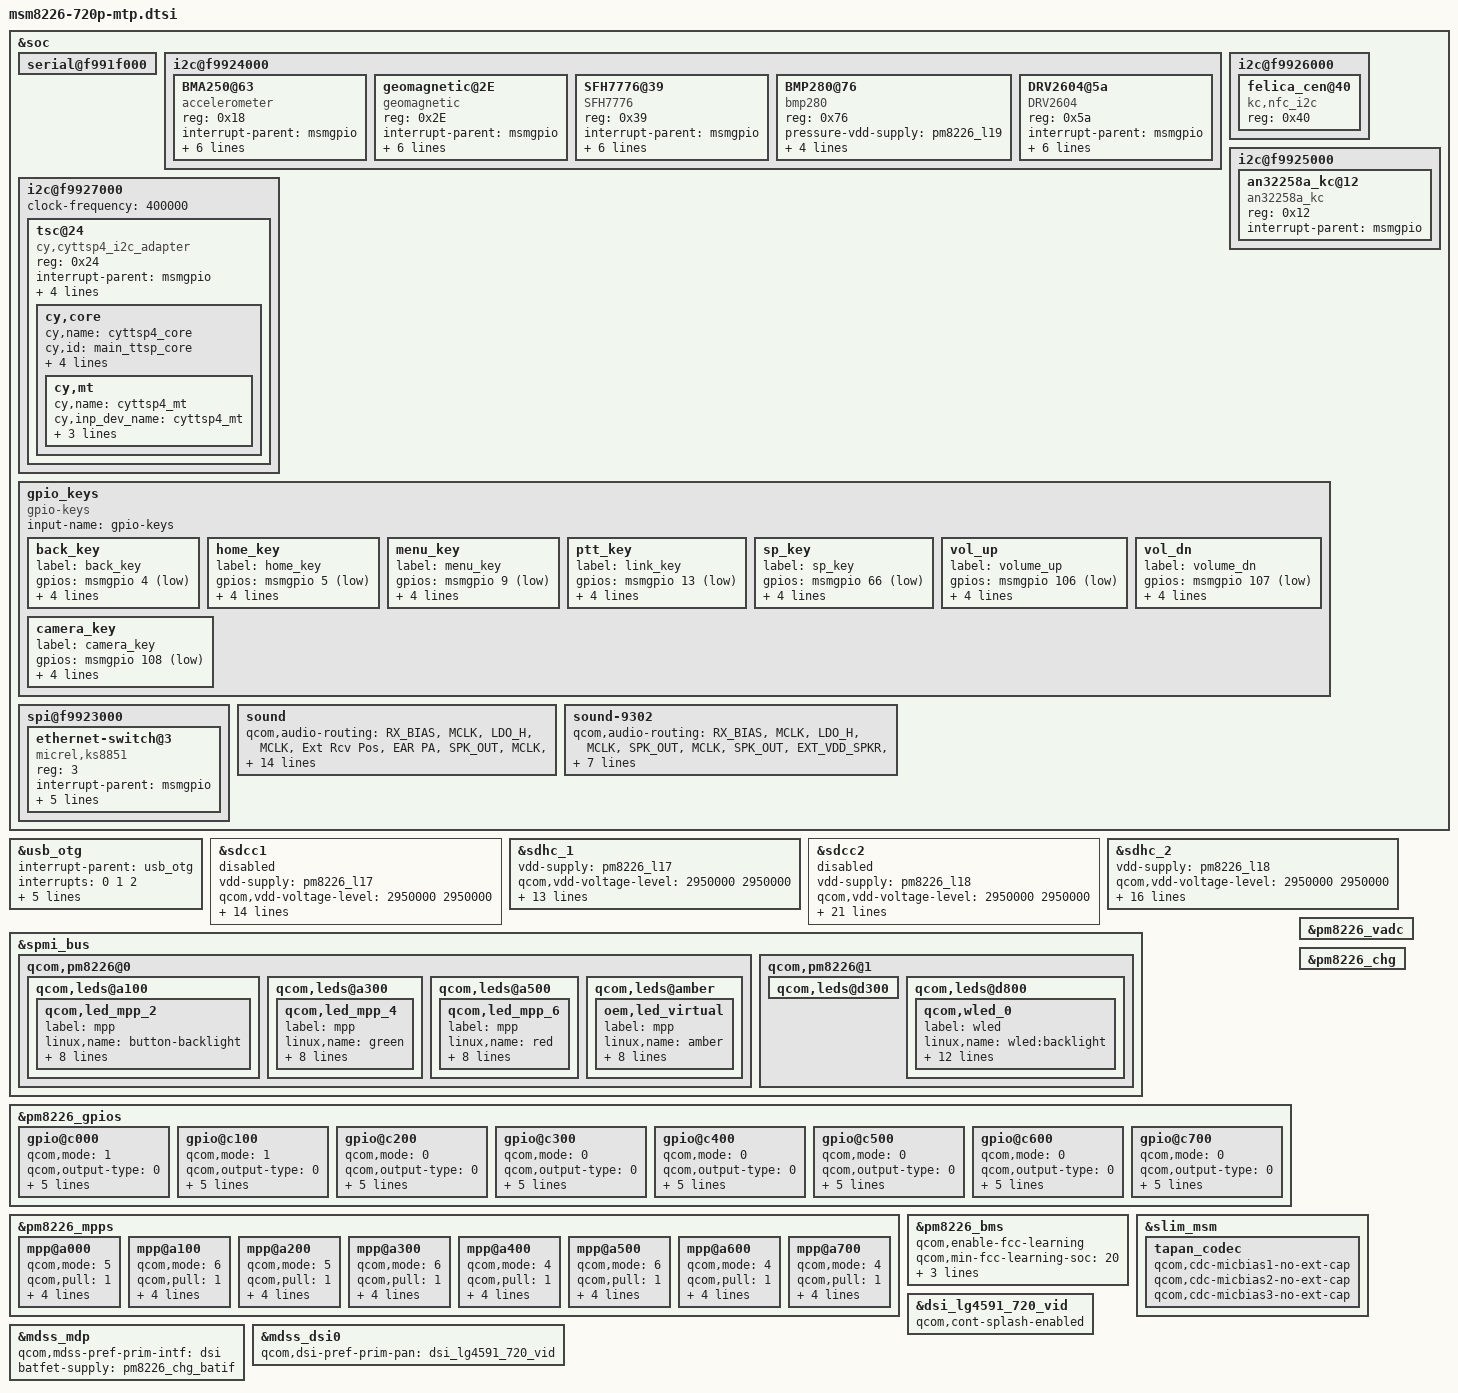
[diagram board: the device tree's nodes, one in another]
/* Copyright (c) 2013, The Linux Foundation. All rights reserved.
 *
 * This program is free software; you can redistribute it and/or modify
 * it under the terms of the GNU General Public License version 2 and
 * only version 2 as published by the Free Software Foundation.
 *
 * This program is distributed in the hope that it will be useful,
 * but WITHOUT ANY WARRANTY; without even the implied warranty of
 * MERCHANTABILITY or FITNESS FOR A PARTICULAR PURPOSE.  See the
 * GNU General Public License for more details.
 */
/*
 * This software is contributed or developed by KYOCERA Corporation.
 * (C) 2014 KYOCERA Corporation
 */

/include/ "msm8226-camera-sensor-mtp.dtsi"

&soc {
	serial@f991f000 {
		status = "ok";
	};
	i2c@f9924000 {
		BMA250@63 {
			compatible = "accelerometer";
			reg = <0x18>;
			interrupt-parent = <&msmgpio>;
			interrupts = <63 0x2008>;
			accel-vdd-supply = <&pm8226_l19>;
			accel-vdd-min-voltage = <2800000>;
			accel-vdd-max-voltage = <2800000>;
			accel-vdd-load-current = <10000>;
			vcc_i2c-supply = <&pm8226_l6>;
		};
		geomagnetic@2E {
			compatible = "geomagnetic";
			reg = <0x2E>;
			interrupt-parent = <&msmgpio>;
			interrupts = <66 0x2008>;
			geomagnetic-vdd-supply = <&pm8226_l19>;
			geomagnetic-vdd-min-voltage = <2800000>;
			geomagnetic-vdd-max-voltage = <2800000>;
			geomagnetic-vdd-load-current = <10000>;
			vcc_i2c-supply = <&pm8226_l6>;
		};
		SFH7776@39 {
			compatible = "SFH7776";
			reg = <0x39>;
			interrupt-parent = <&msmgpio>;
			interrupts = <65 0x2008>;
			light-prox-vdd-supply = <&pm8226_l19>;
			light-prox-vdd-min-voltage = <2800000>;
			light-prox-vdd-max-voltage = <2800000>;
			light-prox-vdd-load-current = <10000>;
			vcc_i2c-supply = <&pm8226_l6>;
		};
		BMP280@76 {
			compatible = "bmp280";
			reg = <0x76>;
			pressure-vdd-supply = <&pm8226_l19>;
			pressure-vdd-min-voltage = <2800000>;
			pressure-vdd-max-voltage = <2800000>;
			pressure-vdd-load-current = <10000>;
			vcc_i2c-supply = <&pm8226_l6>;
		};
		DRV2604@5a {
			compatible = "DRV2604";
			reg = <0x5a>;
			interrupt-parent = <&msmgpio>;
			interrupts = <98 0x2008>;
			vib-vdd-supply = <&pm8226_l19>;
			vib-vdd-min-voltage = <2800000>;
			vib-vdd-max-voltage = <2800000>;
			vib-vdd-load-current = <10000>;
			vcc_i2c-supply = <&pm8226_l6>;
		};
	};

	i2c@f9926000 {
		felica_cen@40 {
			status = "okay";
			compatible = "kc,nfc_i2c";
			reg = <0x40>;
		};
	};

	i2c@f9927000 { /* BLSP1 QUP5 */
		clock-frequency = <400000>;

		tsc@24 {
			compatible = "cy,cyttsp4_i2c_adapter";
			reg = <0x24>;
			interrupt-parent = <&msmgpio>;
			interrupts = <17 0x2008>;
			vdd-supply = <&pm8226_l23>;
			vcc_i2c-supply = <&pm8226_l6>;
			cy,adapter_id = "cyttsp4_i2c_adapter";

			cy,core {

				cy,name = "cyttsp4_core";
				cy,id = "main_ttsp_core";

				cy,irq_gpio = <17>;
				cy,rst_gpio = <16>;

				cy,max_xfer_len = <0x100>;

				cy,flags = <0>;

				cy,mt {
					cy,name = "cyttsp4_mt";

					cy,inp_dev_name = "cyttsp4_mt";
					cy,flags = <0x80>;
					cy,abs =
						<0x35 0 960 0 0
						0x36 0 540 0 0
						0x3a 0 200 0 0
						0xffff 0 255 0 0
						0x39 0 15 0 0
						0x30 0 20 0 0
						0x31 0 20 0 0
						0x34 0xfffffed7 127 0 0>;

				};
			};
		};
	};

	i2c@f9925000 { /* BLSP1 QUP3 */
		an32258a_kc@12 {
			compatible = "an32258a_kc";
			reg = <0x12>;
			interrupt-parent = <&msmgpio>;
		};
	};
	gpio_keys {
		compatible = "gpio-keys";
		input-name = "gpio-keys";

		back_key {
			label = "back_key";
			gpios = <&msmgpio 4 0x1>;
			linux,input-type = <1>;
			linux,code = <0x9e>;
			gpio-key,wakeup;
			debounce-interval = <20>;
		};
		home_key {
			label = "home_key";
			gpios = <&msmgpio 5 0x1>;
			linux,input-type = <1>;
			linux,code = <0x66>;
			gpio-key,wakeup;
			debounce-interval = <20>;
		};

		menu_key {
			label = "menu_key";
			gpios = <&msmgpio 9 0x1>;
			linux,input-type = <1>;
			linux,code = <0x8b>;
			gpio-key,wakeup;
			debounce-interval = <20>;
		};

		ptt_key {
			label = "link_key";
			gpios = <&msmgpio 13 0x1>;
			linux,input-type = <1>;
			linux,code = <0xe7>;
			gpio-key,wakeup;
			debounce-interval = <20>;
		};

		sp_key  {
			label = "sp_key";
			gpios = <&msmgpio 66 0x1>;
			linux,input-type = <1>;
			linux,code = <0xd5>;
			gpio-key,wakeup;
			debounce-interval = <20>;
		};

		vol_up {
			label = "volume_up";
			gpios = <&msmgpio 106 0x1>;
			linux,input-type = <1>;
			linux,code = <0x73>;
			gpio-key,wakeup;
			debounce-interval = <20>;
		};

		vol_dn {
			label = "volume_dn";
			gpios = <&msmgpio 107 0x1>;
			linux,input-type = <1>;
			linux,code = <0x72>;
			gpio-key,wakeup;
			debounce-interval = <20>;
		};

		camera_key {
			label = "camera_key";
			gpios = <&msmgpio 108 0x1>;
			linux,input-type = <1>;
			linux,code = <0xd4>;
			gpio-key,wakeup;
			debounce-interval = <20>;
		};

	};

	spi@f9923000 {
		ethernet-switch@3 {
			compatible = "micrel,ks8851";
			reg = <3>;
			interrupt-parent = <&msmgpio>;
			interrupts = <115 0x8>;
			spi-max-frequency = <4800000>;
			rst-gpio = <&msmgpio 114 0>;
			vdd-io-supply = <&pm8226_lvs1>;
			vdd-phy-supply = <&pm8226_lvs1>;
		};
	};

	sound {
		qcom,audio-routing =
			"RX_BIAS", "MCLK",
			"LDO_H", "MCLK",
			"Ext Rcv Pos", "EAR PA",
			"SPK_OUT", "MCLK",
			"SPK_OUT", "EXT_VDD_SPKR",
			"Lineout_1 spk amp", "LINEOUT1_SPK",
			"Lineout_2 spk amp", "LINEOUT2_SPK",
			"AMIC1", "MIC BIAS1 External",
			"MIC BIAS1 External", "Handset Main Mic",
			"AMIC2", "MIC BIAS2 External",
			"MIC BIAS2 External", "Headset Mic",
			"AMIC3", "MIC BIAS3 External",
			"MIC BIAS3 External", "Handset Sub Mic";

		qcom,cdc-mclk-gpios = <&pm8226_gpios 1 0>;
		qcom,cdc-vdd-spkr-gpios = <&pm8226_gpios 2 0>;
		kc,rcv-amp-gpio-on = <&msmgpio 75 0>;
		kc,spk-amp-gpio-ctrl = <&msmgpio 76 0>;
		kc,jack-gpios = <&msmgpio 109 0>;
		kc,jack-sw-gpios = <&msmgpio 38 0>;
		qcom,headset-jack-type-NC;
	};

	sound-9302 {
		qcom,audio-routing =
			"RX_BIAS", "MCLK",
			"LDO_H", "MCLK",
			"SPK_OUT", "MCLK",
			"SPK_OUT", "EXT_VDD_SPKR",
			"AMIC1", "MIC BIAS1 Internal1",
			"MIC BIAS1 Internal1", "Handset Mic",
			"AMIC2", "MIC BIAS2 External",
			"MIC BIAS2 External", "Headset Mic",
			"AMIC3", "MIC BIAS1 External",
			"MIC BIAS1 External", "Handset Mic";

		qcom,cdc-mclk-gpios = <&pm8226_gpios 1 0>;
		qcom,cdc-vdd-spkr-gpios = <&pm8226_gpios 2 0>;
	};
};

&usb_otg {
	#address-cells = <0>;
	interrupt-parent = <&usb_otg>;
	interrupts = <0 1 2>;
	#interrupt-cells = <1>;
	interrupt-map-mask = <0xffffffff>;
	interrupt-map = <0 &intc 0 134 0
			1 &intc 0 140 0
			2 &spmi_bus 0x0 0x0 0x9 0x0>;
	interrupt-names = "core_irq", "async_irq", "pmic_id_irq";

	qcom,hsusb-otg-mode = <3>;
	vbus_otg-supply = <&pm8226_chg_otg>;
};

&sdcc1 {
	vdd-supply = <&pm8226_l17>;
	qcom,vdd-voltage-level = <2950000 2950000>;
	qcom,vdd-current-level = <800 500000>;

	vdd-io-supply = <&pm8226_l6>;
	qcom,vdd-io-always-on;
	qcom,vdd-io-voltage-level = <1800000 1800000>;
	qcom,vdd-io-current-level = <250 154000>;

	qcom,pad-pull-on = <0x0 0x3 0x3>; /* no-pull, pull-up, pull-up */
	qcom,pad-pull-off = <0x0 0x3 0x3>; /* no-pull, pull-up, pull-up */
	qcom,pad-drv-on = <0x7 0x3 0x3>; /* 16mA, 8mA, 8mA */
	qcom,pad-drv-off = <0x0 0x0 0x0>; /* 2mA, 2mA, 2mA */

	qcom,clk-rates = <400000 25000000 50000000 100000000 200000000>;
	qcom,sup-voltages = <2950 2950>;

	qcom,bus-speed-mode = "HS200_1p8v", "DDR_1p8v";
	qcom,nonremovable;

	status = "disabled";
};

&sdhc_1 {
	vdd-supply = <&pm8226_l17>;
	qcom,vdd-voltage-level = <2950000 2950000>;
	qcom,vdd-current-level = <800 500000>;

	vdd-io-supply = <&pm8226_l6>;
	qcom,vdd-io-always-on;
	qcom,vdd-io-voltage-level = <1800000 1800000>;
	qcom,vdd-io-current-level = <250 154000>;

	qcom,pad-pull-on = <0x0 0x3 0x3>; /* no-pull, pull-up, pull-up */
	qcom,pad-pull-off = <0x0 0x3 0x3>; /* no-pull, pull-up, pull-up */
	qcom,pad-drv-on = <0x7 0x3 0x3>; /* 16mA, 8mA, 8mA */
	qcom,pad-drv-off = <0x0 0x0 0x0>; /* 2mA, 2mA, 2mA */

	qcom,clk-rates = <400000 25000000 50000000 100000000 200000000>;
	qcom,bus-speed-mode = "HS200_1p8v", "DDR_1p8v";
	qcom,nonremovable;

	status = "ok";
};

&sdcc2 {
	vdd-supply = <&pm8226_l18>;
	qcom,vdd-voltage-level = <2950000 2950000>;
	qcom,vdd-current-level = <9000 800000>;

	vdd-io-supply = <&pm8226_l21>;
	qcom,vdd-io-voltage-level = <1800000 2950000>;
	qcom,vdd-io-current-level = <6 22000>;

	qcom,pad-pull-on = <0x0 0x0 0x0>; /* no-pull, no-pull, no-pull */
	qcom,pad-pull-off = <0x1 0x1 0x1>; /* pull-down, pull-down, pull-down */
	qcom,pad-drv-on = <0x5 0x3 0x2>; /* 12mA, 8mA, 6mA */
	qcom,pad-drv-off = <0x0 0x0 0x0>; /* 2mA, 2mA, 2mA */

	qcom,clk-rates = <384000 24000000 48000000 96000000 200000000>;
	qcom,sup-voltages = <2950 2950>;

	qcom,xpc;
	qcom,bus-speed-mode = "SDR12", "SDR25", "SDR50", "DDR50", "SDR104";
	qcom,current-limit = <600>; #address-cells = <0>; interrupt-parent = <&sdcc2>;
	interrupts = <0 1 2>;
	#interrupt-cells = <1>;
	interrupt-map-mask = <0xffffffff>;
	interrupt-map = <0 &intc 0 125 0
			1 &intc 0 220 0
			2 &msmgpio 62 0x3>;
	interrupt-names = "core_irq", "bam_irq", "status_irq";
	cd-gpios = <&msmgpio 62 0x1>;

	status = "disabled";
};

&sdhc_2 {
	vdd-supply = <&pm8226_l18>;
	qcom,vdd-voltage-level = <2950000 2950000>;
	qcom,vdd-current-level = <9000 800000>;

	vdd-io-supply = <&pm8226_l21>;
	qcom,vdd-io-voltage-level = <1800000 2950000>;
	qcom,vdd-io-current-level = <6 22000>;

	qcom,pad-pull-on = <0x0 0x0 0x0>; /* no-pull, no-pull, no-pull */
	qcom,pad-pull-off = <0x1 0x1 0x1>; /* pull-down, pull-down, pull-down */
	qcom,pad-drv-on = <0x5 0x3 0x2>; /* 12mA, 8mA, 6mA */
	qcom,pad-drv-off = <0x0 0x0 0x0>; /* 2mA, 2mA, 2mA */

	qcom,clk-rates = <384000 24000000 48000000 96000000 200000000>;

	#address-cells = <0>;
	interrupt-parent = <&sdhc_2>;
	interrupts = <0 1 2>;
	#interrupt-cells = <1>;
	interrupt-map-mask = <0xffffffff>;
	interrupt-map = <0 &intc 0 125 0
			1 &intc 0 221 0
			2 &msmgpio 62 0x3>;
	interrupt-names = "hc_irq", "pwr_irq", "status_irq";
	cd-gpios = <&msmgpio 62 0x1>;

	status = "ok";
};

&spmi_bus {
	qcom,pm8226@0 {
		qcom,leds@a100 {
			status = "okay";
			qcom,led_mpp_2 {
				label = "mpp";
				linux,name = "button-backlight";
				linux,default-trigger = "none";
				qcom,default-state = "off";
				qcom,max-current = <10>;
				qcom,current-setting = <10>;
				qcom,id = <6>;
				qcom,mode = "manual";
				qcom,source-sel = <1>;
				qcom,mode-ctrl = <0x60>;
			};
		};

		qcom,leds@a300 {
			status = "okay";
			qcom,led_mpp_4 {
				label = "mpp";
				linux,name = "green";
				linux,default-trigger = "none";
				qcom,default-state = "off";
				qcom,max-current = <5>;
				qcom,current-setting = <5>;
				qcom,id = <6>;
				qcom,mode = "manual";
				qcom,source-sel = <1>;
				qcom,mode-ctrl = <0x60>;
			};
		};

		qcom,leds@a500 {
			status = "okay";
			qcom,led_mpp_6 {
				label = "mpp";
				linux,name = "red";
				linux,default-trigger = "none";
				qcom,default-state = "off";
				qcom,max-current = <5>;
				qcom,current-setting = <5>;
				qcom,id = <6>;
				qcom,mode = "manual";
				qcom,source-sel = <1>;
				qcom,mode-ctrl = <0x60>;
			};
		};

		qcom,leds@amber {
			status = "okay";
			oem,led_virtual {
				label = "mpp";
				linux,name = "amber";
				linux,default-trigger = "none";
				qcom,default-state = "off";
				qcom,max-current = <5>;
				qcom,current-setting = <5>;
				qcom,id = <6>;
				qcom,mode = "manual";
				qcom,source-sel = <1>;
				qcom,mode-ctrl = <0x60>;
			};
		};
	};

	qcom,pm8226@1 {
                qcom,leds@d300 {
                        status = "okay";
                };

		qcom,leds@d800 {
			status = "okay";
			qcom,wled_0 {
				label = "wled";
				linux,name = "wled:backlight";
				linux,default-trigger = "bkl-trigger";
				qcom,cs-out-en;
				qcom,op-fdbck = <1>;
				qcom,default-state = "off";
				qcom,max-current = <25>;
				qcom,ctrl-delay-us = <0>;
				qcom,boost-curr-lim = <3>;
				qcom,cp-sel = <0>;
				qcom,switch-freq = <11>;
				qcom,ovp-val = <0>;
				qcom,num-strings = <1>;
				qcom,id = <0>;
			};
		};

	};
};

&pm8226_gpios {
	gpio@c000 { /* GPIO 1 */
		qcom,mode = <1>;
		qcom,output-type = <0>;
		qcom,pull = <5>;
		qcom,vin-sel = <3>;
		qcom,out-strength = <1>;
		qcom,src-sel = <2>;
		qcom,master-en = <1>;
	};

	gpio@c100 { /* GPIO 2 */
		qcom,mode = <1>;
		qcom,output-type = <0>;
		qcom,pull = <5>;
		qcom,vin-sel = <3>;
		qcom,out-strength = <1>;
		qcom,src-sel = <2>;
		qcom,master-en = <1>;
	};

	gpio@c200 { /* GPIO 3 */
		qcom,mode = <0>;
		qcom,output-type = <0>;
		qcom,pull = <0>;
		qcom,vin-sel = <3>;
		qcom,out-strength = <1>;
		qcom,src-sel = <0>;
		qcom,master-en = <1>;
	};

	gpio@c300 { /* GPIO 4 */
		qcom,mode = <0>;
		qcom,output-type = <0>;
		qcom,pull = <4>;
		qcom,vin-sel = <3>;
		qcom,out-strength = <1>;
		qcom,src-sel = <0>;
		qcom,master-en = <1>;
	};

	gpio@c400 { /* GPIO 5 */
		qcom,mode = <0>;
		qcom,output-type = <0>;
		qcom,pull = <0>;
		qcom,vin-sel = <3>;
		qcom,out-strength = <1>;
		qcom,src-sel = <0>;
		qcom,master-en = <1>;
	};

	gpio@c500 { /* GPIO 6 */
		qcom,mode = <0>;
		qcom,output-type = <0>;
		qcom,pull = <4>;
		qcom,vin-sel = <3>;
		qcom,out-strength = <1>;
		qcom,src-sel = <0>;
		qcom,master-en = <1>;
	};

	gpio@c600 { /* GPIO 7 */
		qcom,mode = <0>;
		qcom,output-type = <0>;
		qcom,pull = <5>;
		qcom,vin-sel = <3>;
		qcom,out-strength = <1>;
		qcom,src-sel = <0>;
		qcom,master-en = <1>;
	};

	gpio@c700 { /* GPIO 8 */
		qcom,mode = <0>;
		qcom,output-type = <0>;
		qcom,pull = <4>;
		qcom,vin-sel = <3>;
		qcom,out-strength = <1>;
		qcom,src-sel = <0>;
		qcom,master-en = <1>;
	};
};

&pm8226_mpps {
	mpp@a000 { /* MPP 1 */
		qcom,mode = <5>;
		qcom,pull = <1>;
		qcom,vin-sel = <3>;
		qcom,src-sel = <0>;
		qcom,master-en = <1>;
		qcom,aout-ref= <0>;
	};

	mpp@a100 { /* MPP 2 */
		qcom,mode = <6>;
		qcom,pull = <1>;
		qcom,vin-sel = <3>;
		qcom,src-sel = <0>;
		qcom,master-en = <1>;
		qcom,cs-out = <0>;
	};

	mpp@a200 { /* MPP 3 */
		qcom,mode = <5>;
		qcom,pull = <1>;
		qcom,vin-sel = <3>;
		qcom,src-sel = <0>;
		qcom,master-en = <1>;
		qcom,aout-ref= <0>;
	};

	mpp@a300 { /* MPP 4 */
		qcom,mode = <6>;
		qcom,pull = <1>;
		qcom,vin-sel = <3>;
		qcom,src-sel = <0>;
		qcom,master-en = <1>;
		qcom,cs-out = <0>;
	};

	mpp@a400 { /* MPP 5 */
		qcom,mode = <4>;
		qcom,pull = <1>;
		qcom,vin-sel = <3>;
		qcom,src-sel = <0>;
		qcom,master-en = <1>;
		qcom,ain-route = <0>;
	};

	mpp@a500 { /* MPP 6 */
		qcom,mode = <6>;
		qcom,pull = <1>;
		qcom,vin-sel = <3>;
		qcom,src-sel = <0>;
		qcom,master-en = <1>;
		qcom,cs-out = <0>;
	};

	mpp@a600 { /* MPP 7 */
		qcom,mode = <4>;
		qcom,pull = <1>;	/* The hardware ignores the configuration because operating fot this MPP is NOT bidirectional mode. */
		qcom,vin-sel = <3>;
		qcom,src-sel = <0>;
		qcom,master-en = <1>;
		qcom,ain-route = <2>;
	};

	mpp@a700 { /* MPP 8 */
		qcom,mode = <4>;
		qcom,pull = <1>;
		qcom,vin-sel = <3>;
		qcom,src-sel = <0>;
		qcom,master-en = <1>;
		qcom,ain-route = <3>;
	};
};

&pm8226_vadc {

};

&pm8226_bms {
	status = "ok";
	qcom,enable-fcc-learning;
	qcom,min-fcc-learning-soc = <20>;
	qcom,min-fcc-ocv-pc = <30>;
	qcom,min-fcc-learning-samples = <5>;
	qcom,fcc-resolution = <13>;
};

&pm8226_chg {
	status = "ok";
};

&slim_msm {
	tapan_codec {
		qcom,cdc-micbias1-no-ext-cap;
		qcom,cdc-micbias2-no-ext-cap;
		qcom,cdc-micbias3-no-ext-cap;
	};
};

&mdss_mdp {
	qcom,mdss-pref-prim-intf = "dsi";
	batfet-supply = <&pm8226_chg_batif>;
};

&mdss_dsi0 {
	qcom,dsi-pref-prim-pan = <&dsi_lg4591_720_vid>;
};

&dsi_lg4591_720_vid {
	qcom,cont-splash-enabled;
};
